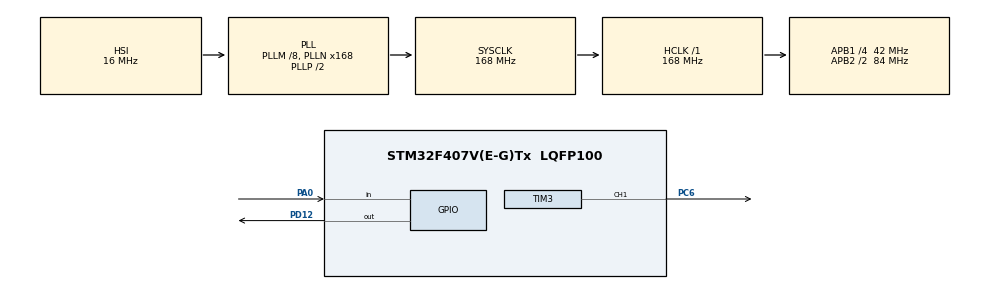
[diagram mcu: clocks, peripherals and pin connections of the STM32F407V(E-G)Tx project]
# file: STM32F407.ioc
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Mcu.Family=STM32F4
Mcu.Name=STM32F407V(E-G)Tx
Mcu.Package=LQFP100
NVIC.PriorityGroup=NVIC_PRIORITYGROUP_4
PA0-WKUP.Signal=GPIO_Input
PA13.Mode=Serial_Wire
PA13.Signal=SYS_JTMS-SWDIO
PA14.Mode=Serial_Wire
PA14.Signal=SYS_JTCK-SWCLK
PC6.Signal=S_TIM3_CH1
PD12.Signal=GPIO_Output
PH0-OSC_IN.Mode=HSE-External-Oscillator
PH0-OSC_IN.Signal=RCC_OSC_IN
PH1-OSC_OUT.Mode=HSE-External-Oscillator
PH1-OSC_OUT.Signal=RCC_OSC_OUT
ProjectManager.HeapSize=0x200
ProjectManager.StackSize=0x400
ProjectManager.TargetToolchain=CMake
RCC.48MHZClocksFreq_Value=84000000
RCC.AHBFreq_Value=168000000
RCC.APB1CLKDivider=RCC_HCLK_DIV4
RCC.APB1Freq_Value=42000000
RCC.APB1TimFreq_Value=84000000
RCC.APB2CLKDivider=RCC_HCLK_DIV2
RCC.APB2Freq_Value=84000000
RCC.APB2TimFreq_Value=168000000
RCC.CortexFreq_Value=168000000
RCC.HCLKFreq_Value=168000000
RCC.HSE_VALUE=25000000
RCC.HSI_VALUE=16000000
RCC.LSE_VALUE=32768
RCC.PLLM=8
RCC.PLLN=168
RCC.SYSCLKFreq_VALUE=168000000
RCC.SYSCLKSource=RCC_SYSCLKSOURCE_PLLCLK
RCC.VCOOutputFreq_Value=336000000
SH.S_TIM3_CH1.0=TIM3_CH1,PWM Generation1 CH1
TIM3.AutoReloadPreload=TIM_AUTORELOAD_PRELOAD_ENABLE
TIM3.Channel-PWM\ Generation1\ CH1=TIM_CHANNEL_1
TIM3.Period=19999
TIM3.Prescaler=83
TIM3.Pulse-PWM\ Generation1\ CH1=1000
VP_TIM3_VS_ClockSourceINT.Mode=Internal
board=custom

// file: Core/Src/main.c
/* USER CODE BEGIN Header */
/**
  ******************************************************************************
  * @file           : main.c
  * @brief          : Main program body
  ******************************************************************************
  * @attention
  *
  * Copyright (c) 2026 STMicroelectronics.
  * All rights reserved.
  *
  * This software is licensed under terms that can be found in the LICENSE file
  * in the root directory of this software component.
  * If no LICENSE file comes with this software, it is provided AS-IS.
  *
  ******************************************************************************
  */
/* USER CODE END Header */
#include "main.h"
#include "tim.h"
#include "gpio.h"

/* USER CODE BEGIN Includes */
#include "esc.h"
/* USER CODE END Includes */

/* USER CODE BEGIN PD */
#define THROTTLE_STEP_PERCENT   5U    /* moi lan bam nut tang 5% */
#define THROTTLE_MAX_PERCENT    100U   /* gioi han khi test, vuot qua thi ve 0 */
#define BUTTON_DEBOUNCE_MS      30U
/* USER CODE END PD */

/* USER CODE BEGIN PV */
static ESC_Handle esc;
/* USER CODE END PV */

void SystemClock_Config(void);

int main(void)
{

  /* MCU Configuration--------------------------------------------------------*/

  /* Reset of all peripherals, Initializes the Flash interface and the Systick. */
  HAL_Init();

  /* Configure the system clock */
  SystemClock_Config();

  /* Initialize all configured peripherals */
  MX_GPIO_Init();
  MX_TIM3_Init();
  /* USER CODE BEGIN 2 */
  if (ESC_Init(&esc, &htim3, TIM_CHANNEL_1) != HAL_OK)
  {
    Error_Handler();
  }
  ESC_Arm(&esc);
  HAL_GPIO_WritePin(GPIOD, GPIO_PIN_12, GPIO_PIN_SET);   /* LED sang: da arm */

  uint8_t throttle = 0;
  GPIO_PinState last_button = GPIO_PIN_RESET;
  /* USER CODE END 2 */

  /* Infinite loop */
  while (1)
  {

    /* USER CODE BEGIN 3 */
    /* Nut User (PA0) tich cuc muc cao: moi lan bam tang ga mot nac */
    GPIO_PinState button = HAL_GPIO_ReadPin(GPIOA, GPIO_PIN_0);
    if (button != last_button)
    {
      HAL_Delay(BUTTON_DEBOUNCE_MS);
      button = HAL_GPIO_ReadPin(GPIOA, GPIO_PIN_0);
      if (button == GPIO_PIN_SET && last_button == GPIO_PIN_RESET)
      {
        throttle += THROTTLE_STEP_PERCENT;
        if (throttle > THROTTLE_MAX_PERCENT)
        {
          throttle = 0;
        }
        ESC_SetThrottle(&esc, throttle);
      }
      last_button = button;
    }
  }
  /* USER CODE END 3 */
}

void SystemClock_Config(void)
{
  RCC_OscInitTypeDef RCC_OscInitStruct = {0};
  RCC_ClkInitTypeDef RCC_ClkInitStruct = {0};

  /** Configure the main internal regulator output voltage
  */
  __HAL_RCC_PWR_CLK_ENABLE();
  __HAL_PWR_VOLTAGESCALING_CONFIG(PWR_REGULATOR_VOLTAGE_SCALE1);

  /** Initializes the RCC Oscillators according to the specified parameters
  * in the RCC_OscInitTypeDef structure.
  */
  RCC_OscInitStruct.OscillatorType = RCC_OSCILLATORTYPE_HSI;
  RCC_OscInitStruct.HSIState = RCC_HSI_ON;
  RCC_OscInitStruct.HSICalibrationValue = RCC_HSICALIBRATION_DEFAULT;
  RCC_OscInitStruct.PLL.PLLState = RCC_PLL_ON;
  RCC_OscInitStruct.PLL.PLLSource = RCC_PLLSOURCE_HSI;
  RCC_OscInitStruct.PLL.PLLM = 8;
  RCC_OscInitStruct.PLL.PLLN = 168;
  RCC_OscInitStruct.PLL.PLLP = RCC_PLLP_DIV2;
  RCC_OscInitStruct.PLL.PLLQ = 4;
  if (HAL_RCC_OscConfig(&RCC_OscInitStruct) != HAL_OK)
  {
    Error_Handler();
  }

  /** Initializes the CPU, AHB and APB buses clocks
  */
  RCC_ClkInitStruct.ClockType = RCC_CLOCKTYPE_HCLK|RCC_CLOCKTYPE_SYSCLK
                              |RCC_CLOCKTYPE_PCLK1|RCC_CLOCKTYPE_PCLK2;
  RCC_ClkInitStruct.SYSCLKSource = RCC_SYSCLKSOURCE_PLLCLK;
  RCC_ClkInitStruct.AHBCLKDivider = RCC_SYSCLK_DIV1;
  RCC_ClkInitStruct.APB1CLKDivider = RCC_HCLK_DIV4;
  RCC_ClkInitStruct.APB2CLKDivider = RCC_HCLK_DIV2;

  if (HAL_RCC_ClockConfig(&RCC_ClkInitStruct, FLASH_LATENCY_5) != HAL_OK)
  {
    Error_Handler();
  }
}

void Error_Handler(void)
{
  __disable_irq();
  while (1)
  {
  }
}
